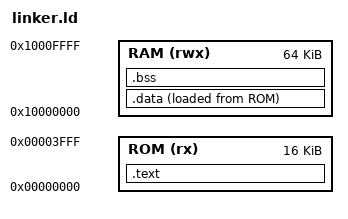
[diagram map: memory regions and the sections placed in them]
ENTRY(_start)

MEMORY
{
    ROM (rx)  : ORIGIN = 0x00000000, LENGTH = 16K
    RAM (rwx) : ORIGIN = 0x10000000, LENGTH = 64K
}

SECTIONS
{
    .text : {
        KEEP(*(.init))
        *(.text*)
        *(.rodata*)
    } > ROM

    .data : {
        *(.data*)
    } > RAM AT > ROM

    .bss : {
        *(.bss*)
        *(COMMON)
    } > RAM

    . = ALIGN(4);
    _stack_top = ORIGIN(RAM) + LENGTH(RAM);
}
